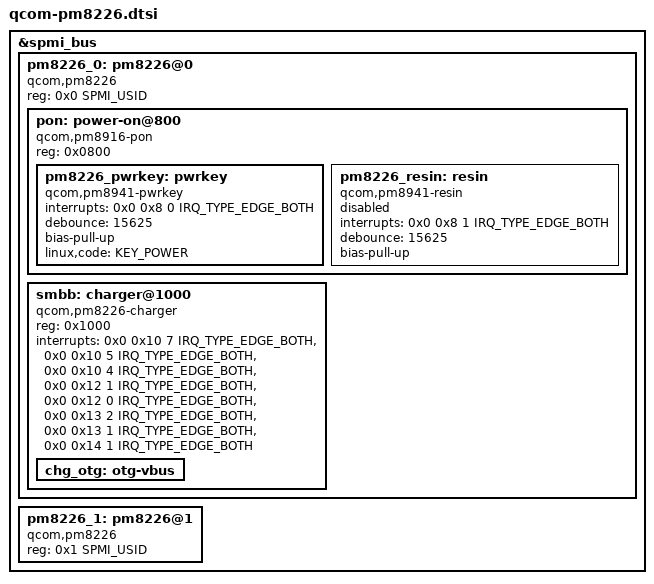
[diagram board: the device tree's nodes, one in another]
// SPDX-License-Identifier: BSD-3-Clause
#include <dt-bindings/interrupt-controller/irq.h>
#include <dt-bindings/input/input.h>
#include <dt-bindings/spmi/spmi.h>

&spmi_bus {
	pm8226_0: pm8226@0 {
		compatible = "qcom,pm8226", "qcom,spmi-pmic";
		reg = <0x0 SPMI_USID>;
		#address-cells = <1>;
		#size-cells = <0>;

		pon: power-on@800 {
			compatible = "qcom,pm8916-pon";
			reg = <0x0800>;

			pm8226_pwrkey: pwrkey {
				compatible = "qcom,pm8941-pwrkey";
				interrupts = <0x0 0x8 0 IRQ_TYPE_EDGE_BOTH>;
				debounce = <15625>;
				bias-pull-up;
				linux,code = <KEY_POWER>;
			};

			pm8226_resin: resin {
				compatible = "qcom,pm8941-resin";
				interrupts = <0x0 0x8 1 IRQ_TYPE_EDGE_BOTH>;
				debounce = <15625>;
				bias-pull-up;

				status = "disabled";
			};
		};

		smbb: charger@1000 {
			compatible = "qcom,pm8226-charger";
			reg = <0x1000>;
			interrupts = <0x0 0x10 7 IRQ_TYPE_EDGE_BOTH>,
				     <0x0 0x10 5 IRQ_TYPE_EDGE_BOTH>,
				     <0x0 0x10 4 IRQ_TYPE_EDGE_BOTH>,
				     <0x0 0x12 1 IRQ_TYPE_EDGE_BOTH>,
				     <0x0 0x12 0 IRQ_TYPE_EDGE_BOTH>,
				     <0x0 0x13 2 IRQ_TYPE_EDGE_BOTH>,
				     <0x0 0x13 1 IRQ_TYPE_EDGE_BOTH>,
				     <0x0 0x14 1 IRQ_TYPE_EDGE_BOTH>;
			interrupt-names = "chg-done",
					  "chg-fast",
					  "chg-trkl",
					  "bat-temp-ok",
					  "bat-present",
					  "chg-gone",
					  "usb-valid",
					  "dc-valid";

			chg_otg: otg-vbus { };
		};
	};

	pm8226_1: pm8226@1 {
		compatible = "qcom,pm8226", "qcom,spmi-pmic";
		reg = <0x1 SPMI_USID>;
		#address-cells = <1>;
		#size-cells = <0>;
	};
};
